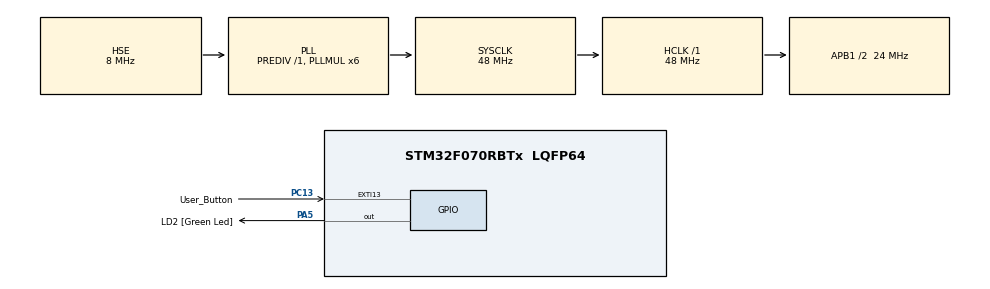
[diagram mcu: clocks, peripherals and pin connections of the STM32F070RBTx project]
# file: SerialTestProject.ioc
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Mcu.Family=STM32F0
Mcu.Name=STM32F070RBTx
Mcu.Package=LQFP64
NVIC.EXTI4_15_IRQn=true\:0\:0\:false\:false\:true\:true\:true
NVIC.TIM6_IRQn=true\:0\:0\:false\:false\:true\:true\:true
NVIC.TIM7_IRQn=true\:0\:0\:false\:false\:true\:true\:true
PA13.GPIO_Label=TMS
PA13.Mode=Serial_Wire
PA13.Signal=SYS_SWDIO
PA14.GPIO_Label=TCK
PA14.Mode=Serial_Wire
PA14.Signal=SYS_SWCLK
PA2.GPIO_Label=USART_TX
PA2.GPIO_Speed=GPIO_SPEED_FREQ_LOW
PA2.Signal=USART2_TX
PA3.GPIO_Label=USART_RX
PA3.GPIO_Speed=GPIO_SPEED_FREQ_LOW
PA3.Signal=USART2_RX
PA5.GPIO_Label=LD2 [Green Led]
PA5.Signal=GPIO_Output
PC13.GPIO_Label=User_Button
PC13.GPIO_ModeDefaultEXTI=GPIO_MODE_IT_FALLING
PC13.Signal=GPXTI13
PC14-OSC32_IN.GPIO_Label=RCC_OSC32_IN
PC14-OSC32_IN.Mode=LSE-External-Oscillator
PC14-OSC32_IN.Signal=RCC_OSC32_IN
PC15-OSC32_OUT.GPIO_Label=RCC_OSC32_OUT
PC15-OSC32_OUT.Mode=LSE-External-Oscillator
PC15-OSC32_OUT.Signal=RCC_OSC32_OUT
PF0-OSC_IN.GPIO_Label=RCC_OSC_IN
PF0-OSC_IN.Mode=HSE-External-Clock-Source
PF0-OSC_IN.Signal=RCC_OSC_IN
PF1-OSC_OUT.GPIO_Label=RCC_OSC_OUT
PF1-OSC_OUT.Signal=RCC_OSC_OUT
ProjectManager.HeapSize=0x200
ProjectManager.StackSize=0x400
ProjectManager.TargetToolchain=STM32CubeIDE
RCC.AHBFreq_Value=48000000
RCC.APB1CLKDivider=RCC_HCLK_DIV2
RCC.APB1Freq_Value=24000000
RCC.APB1TimFreq_Value=48000000
RCC.HCLKFreq_Value=48000000
RCC.PLLMUL=RCC_PLL_MUL6
RCC.PLLSourceVirtual=RCC_PLLSOURCE_HSE
RCC.SYSCLKFreq_VALUE=48000000
RCC.SYSCLKSource=RCC_SYSCLKSOURCE_PLLCLK
TIM6.AutoReloadPreload=TIM_AUTORELOAD_PRELOAD_DISABLE
TIM6.Period=65535
TIM6.Prescaler=553
TIM7.AutoReloadPreload=TIM_AUTORELOAD_PRELOAD_DISABLE
TIM7.Period=65535
TIM7.Prescaler=4
VP_TIM6_VS_ClockSourceINT.Mode=Enable_Timer
VP_TIM7_VS_ClockSourceINT.Mode=Enable_Timer
board=NUCLEO-F070RB

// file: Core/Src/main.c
/* USER CODE BEGIN Header */
/**
 ******************************************************************************
 * @file           : main.c
 * @brief          : Main program body
 ******************************************************************************
 * @attention
 *
 * <h2><center>&copy; Copyright (c) 2019 STMicroelectronics.
 * All rights reserved.</center></h2>
 *
 * This software component is licensed by ST under BSD 3-Clause license,
 * the "License"; You may not use this file except in compliance with the
 * License. You may obtain a copy of the License at:
 *                        opensource.org/licenses/BSD-3-Clause
 *
 ******************************************************************************
 */
/* USER CODE END Header */

#include "main.h"

/* USER CODE BEGIN Includes */
#include <string.h>
#include <math.h>
#include <stdio.h>
/* USER CODE END Includes */

/* USER CODE BEGIN PD */
#define LeftWheel					0x00
#define RightWheel					0x01
#define MeasuringPoints				0x06 //per wheel
#define WheelDivisionVal			0x01 // must evenly divide Measuring points
#define RelevantMeasuringPoints		(MeasuringPoints / WheelDivisionVal) //with how many points should the RPM be calculated
//telemetry
#define MessageLength				30
/* USER CODE END PD */

TIM_HandleTypeDef htim6;
TIM_HandleTypeDef htim7;

/* USER CODE BEGIN PV */
uint16_t tim3Value = 0; //debug
uint16_t tim6Value = 0; //debug
uint16_t tim7Value = 0; //debug

uint16_t TimerSize = (uint16_t) pow(2, 16); //set to timer size
uint32_t WSSSlidingBuffer[2][RelevantMeasuringPoints]; //[Wheel][time between points]
uint32_t RPMOut[2] = { 0, 0 }; //[Wheel]
/* USER CODE END PV */

void SystemClock_Config(void);
static void MX_GPIO_Init(void);
static void MX_TIM6_Init(void);
static void MX_TIM7_Init(void);
/* USER CODE BEGIN PFP */
void setWSSSlidingBuffer(uint8_t, uint16_t);
void calculateRPMValue();
double pow(double, double);
/* USER CODE END PFP */

int main(void) {

	/* MCU Configuration--------------------------------------------------------*/

	/* Reset of all peripherals, Initializes the Flash interface and the Systick. */
	HAL_Init();

	/* USER CODE BEGIN Init */
	for (int i = 0; i < RelevantMeasuringPoints; i++) {
		WSSSlidingBuffer[LeftWheel][i] = TimerSize - 1;
		WSSSlidingBuffer[RightWheel][i] = TimerSize - 1;
	}
	/* USER CODE END Init */

	/* Configure the system clock */
	SystemClock_Config();

	/* Initialize all configured peripherals */
	MX_GPIO_Init();
	MX_TIM6_Init();
	MX_TIM7_Init();

	/* Infinite loop */
	/* USER CODE BEGIN WHILE */
	while (1) {
		calculateRPMValue();
		tim6Value = __HAL_TIM_GET_COUNTER(&htim6);
		tim7Value = __HAL_TIM_GET_COUNTER(&htim7);
		HAL_Delay(100);
		/* USER CODE END WHILE */

	}
}

void SystemClock_Config(void) {
	RCC_OscInitTypeDef RCC_OscInitStruct = { 0 };
	RCC_ClkInitTypeDef RCC_ClkInitStruct = { 0 };

	/** Initializes the CPU, AHB and APB busses clocks
	 */
	RCC_OscInitStruct.OscillatorType = RCC_OSCILLATORTYPE_HSE;
	RCC_OscInitStruct.HSEState = RCC_HSE_BYPASS;
	RCC_OscInitStruct.PLL.PLLState = RCC_PLL_ON;
	RCC_OscInitStruct.PLL.PLLSource = RCC_PLLSOURCE_HSE;
	RCC_OscInitStruct.PLL.PLLMUL = RCC_PLL_MUL6;
	RCC_OscInitStruct.PLL.PREDIV = RCC_PREDIV_DIV1;
	if (HAL_RCC_OscConfig(&RCC_OscInitStruct) != HAL_OK) {
		Error_Handler();
	}
	/** Initializes the CPU, AHB and APB busses clocks
	 */
	RCC_ClkInitStruct.ClockType = RCC_CLOCKTYPE_HCLK | RCC_CLOCKTYPE_SYSCLK
			| RCC_CLOCKTYPE_PCLK1;
	RCC_ClkInitStruct.SYSCLKSource = RCC_SYSCLKSOURCE_PLLCLK;
	RCC_ClkInitStruct.AHBCLKDivider = RCC_SYSCLK_DIV1;
	RCC_ClkInitStruct.APB1CLKDivider = RCC_HCLK_DIV2;

	if (HAL_RCC_ClockConfig(&RCC_ClkInitStruct, FLASH_LATENCY_1) != HAL_OK) {
		Error_Handler();
	}
}

static void MX_TIM6_Init(void) {

	htim6.Instance = TIM6;
	htim6.Init.Prescaler = 553;
	htim6.Init.CounterMode = TIM_COUNTERMODE_UP;
	htim6.Init.Period = 65535;
	htim6.Init.AutoReloadPreload = TIM_AUTORELOAD_PRELOAD_DISABLE;
	if (HAL_TIM_Base_Init(&htim6) != HAL_OK) {
		Error_Handler();
	}

}

static void MX_TIM7_Init(void) {

	htim7.Instance = TIM7;
	htim7.Init.Prescaler = 4;
	htim7.Init.CounterMode = TIM_COUNTERMODE_UP;
	htim7.Init.Period = 65535;
	htim7.Init.AutoReloadPreload = TIM_AUTORELOAD_PRELOAD_DISABLE;
	if (HAL_TIM_Base_Init(&htim7) != HAL_OK) {
		Error_Handler();
	}

}

static void MX_GPIO_Init(void) {
	GPIO_InitTypeDef GPIO_InitStruct = { 0 };

	/* GPIO Ports Clock Enable */
	__HAL_RCC_GPIOC_CLK_ENABLE();
	__HAL_RCC_GPIOF_CLK_ENABLE();
	__HAL_RCC_GPIOA_CLK_ENABLE();

	/*Configure GPIO pin Output Level */
	HAL_GPIO_WritePin(LD2_GPIO_Port, LD2_Pin, GPIO_PIN_RESET);

	/*Configure GPIO pin : User_Button_Pin */
	GPIO_InitStruct.Pin = User_Button_Pin;
	GPIO_InitStruct.Mode = GPIO_MODE_IT_FALLING;
	GPIO_InitStruct.Pull = GPIO_NOPULL;
	HAL_GPIO_Init(User_Button_GPIO_Port, &GPIO_InitStruct);

	/*Configure GPIO pins : USART_TX_Pin USART_RX_Pin */
	GPIO_InitStruct.Pin = USART_TX_Pin | USART_RX_Pin;
	GPIO_InitStruct.Mode = GPIO_MODE_AF_PP;
	GPIO_InitStruct.Pull = GPIO_NOPULL;
	GPIO_InitStruct.Speed = GPIO_SPEED_FREQ_LOW;
	GPIO_InitStruct.Alternate = GPIO_AF1_USART2;
	HAL_GPIO_Init(GPIOA, &GPIO_InitStruct);

	/*Configure GPIO pin : LD2_Pin */
	GPIO_InitStruct.Pin = LD2_Pin;
	GPIO_InitStruct.Mode = GPIO_MODE_OUTPUT_PP;
	GPIO_InitStruct.Pull = GPIO_NOPULL;
	GPIO_InitStruct.Speed = GPIO_SPEED_FREQ_LOW;
	HAL_GPIO_Init(LD2_GPIO_Port, &GPIO_InitStruct);

	/* EXTI interrupt init*/
	HAL_NVIC_SetPriority(EXTI4_15_IRQn, 0, 0);
	HAL_NVIC_EnableIRQ(EXTI4_15_IRQn);

}

/* USER CODE BEGIN 4 */
/**
 * @brief This function slides the WSSSlidingBuffer to the right and fills a new value into [0], while dividing it by the length of the Buffering Array to prevent overflows
 * @param wheel: 0=>left; 1=> right
 * @param NewVal: the new value
 * @retval None
 */
void setWSSSlidingBufferVal(uint8_t wheel, uint16_t NewVal) {
	for (int i = RelevantMeasuringPoints; i > 0; i--) {
		WSSSlidingBuffer[wheel][i] = WSSSlidingBuffer[wheel][i + 1];
	}
	WSSSlidingBuffer[wheel][0] = NewVal;
}

/**
 * @brief This function calculates a RPM value for each wheel from the information in the WSSSlidingBuffer
 * @retval None
 */
void calculateRPMValue() {
	RPMOut[LeftWheel] = 0;
	RPMOut[RightWheel] = 0;

	for (int i = 0; i < RelevantMeasuringPoints; i++) {		//AvgTime
		RPMOut[LeftWheel] += WSSSlidingBuffer[LeftWheel][i];
	}
	RPMOut[LeftWheel] = RPMOut[LeftWheel] / RelevantMeasuringPoints;

	//(Min		*	Clockspeed) /	(TimerValue	*	WheelDivisionVal	*	Prescaler)
	//(6*10^7	*	Sysclock))	/	(RPMOut		*	WheelDivisionVal	*	htim.init.Prescaler)

	RPMOut[LeftWheel] = (60 * SystemCoreClock)
			/ (MeasuringPoints * RPMOut[LeftWheel] * htim6.Init.Prescaler);
}

/* USER CODE END 4 */

void Error_Handler(void) {
}

/************************ (C) COPYRIGHT STMicroelectronics *****END OF FILE****/
